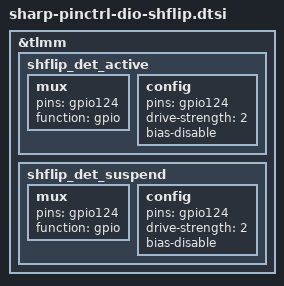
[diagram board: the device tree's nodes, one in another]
/* Copyright (c) 2013-2014, The Linux Foundation. All rights reserved.
 *
 * This program is free software; you can redistribute it and/or modify
 * it under the terms of the GNU General Public License version 2 and
 * only version 2 as published by the Free Software Foundation.
 *
 * This program is distributed in the hope that it will be useful,
 * but WITHOUT ANY WARRANTY; without even the implied warranty of
 * MERCHANTABILITY or FITNESS FOR A PARTICULAR PURPOSE.  See the
 * GNU General Public License for more details.
 */

&tlmm {
	/*****************************************/
	/*  pinctrl customize setting            */
	/*  Flip detection by Hall Sensor        */
	/*****************************************/
	shflip_det_active: shflip_det_active {
		mux {
			pins = "gpio124";
			function = "gpio";
		};
		config {
			pins = "gpio124";
			drive-strength = <2>;	/* 2mA */
			bias-disable;		/* NO pull */
		};
	};

	shflip_det_suspend: shflip_det_suspend {
		mux {
			pins = "gpio124";
			function = "gpio";
		};
		config {
			pins = "gpio124";
			drive-strength = <2>;	/* 2mA */
			bias-disable;		/* NO pull */
		};
	};
};
